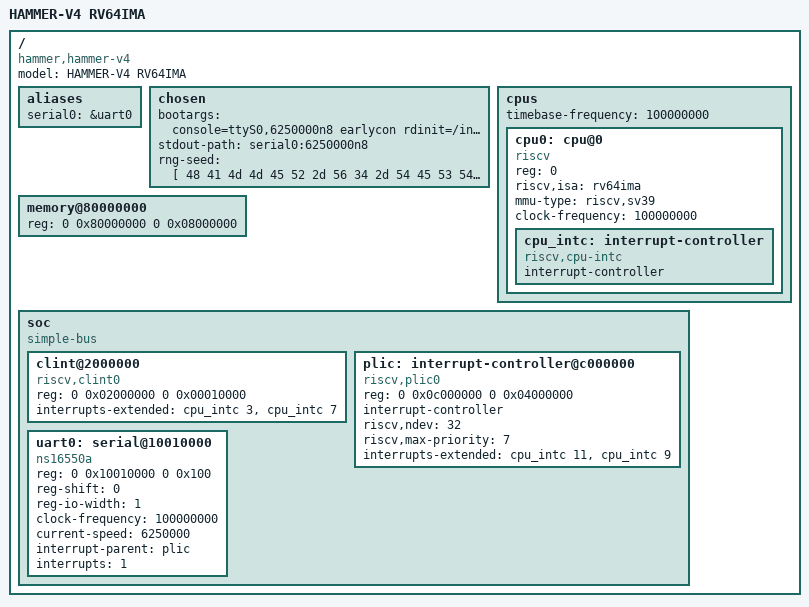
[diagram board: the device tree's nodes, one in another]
/dts-v1/;

/memreserve/ 0x80000000 0x00200000;
/memreserve/ 0x87e00000 0x00200000;

/ {
    #address-cells = <2>;
    #size-cells = <2>;
    compatible = "hammer,hammer-v4";
    model = "HAMMER-V4 RV64IMA";

    aliases {
        serial0 = &uart0;
    };

    chosen {
        bootargs = "console=ttyS0,6250000n8 earlycon rdinit=/init loglevel=7 printk.time=0 nokaslr lpj=500000 panic=0";
        stdout-path = "serial0:6250000n8";
        /* Public deterministic verification input, not production entropy. */
        rng-seed = [
            48 41 4d 4d 45 52 2d 56 34 2d 54 45 53 54 2d 30
            01 02 03 04 05 06 07 08 09 0a 0b 0c 0d 0e 0f 10
            11 12 13 14 15 16 17 18 19 1a 1b 1c 1d 1e 1f 20
            21 22 23 24 25 26 27 28 29 2a 2b 2c 2d 2e 2f 30
        ];
    };

    cpus {
        #address-cells = <1>;
        #size-cells = <0>;
        timebase-frequency = <100000000>;

        cpu0: cpu@0 {
            device_type = "cpu";
            reg = <0>;
            status = "okay";
            compatible = "riscv";
            riscv,isa = "rv64ima";
            mmu-type = "riscv,sv39";
            clock-frequency = <100000000>;
            cpu_intc: interrupt-controller {
                #interrupt-cells = <1>;
                #address-cells = <0>;
                interrupt-controller;
                compatible = "riscv,cpu-intc";
            };
        };
    };

    memory@80000000 {
        device_type = "memory";
        reg = <0 0x80000000 0 0x08000000>;
    };

    soc {
        #address-cells = <2>;
        #size-cells = <2>;
        compatible = "simple-bus";
        ranges;

        clint@2000000 {
            compatible = "riscv,clint0";
            reg = <0 0x02000000 0 0x00010000>;
            interrupts-extended = <&cpu_intc 3>, <&cpu_intc 7>;
        };

        plic: interrupt-controller@c000000 {
            compatible = "riscv,plic0";
            reg = <0 0x0c000000 0 0x04000000>;
            #interrupt-cells = <1>;
            #address-cells = <0>;
            interrupt-controller;
            riscv,ndev = <32>;
            riscv,max-priority = <7>;
            interrupts-extended = <&cpu_intc 11>, <&cpu_intc 9>;
        };

        uart0: serial@10010000 {
            compatible = "ns16550a";
            reg = <0 0x10010000 0 0x100>;
            reg-shift = <0>;
            reg-io-width = <1>;
            clock-frequency = <100000000>;
            current-speed = <6250000>;
            interrupt-parent = <&plic>;
            interrupts = <1>;
        };
    };
};
